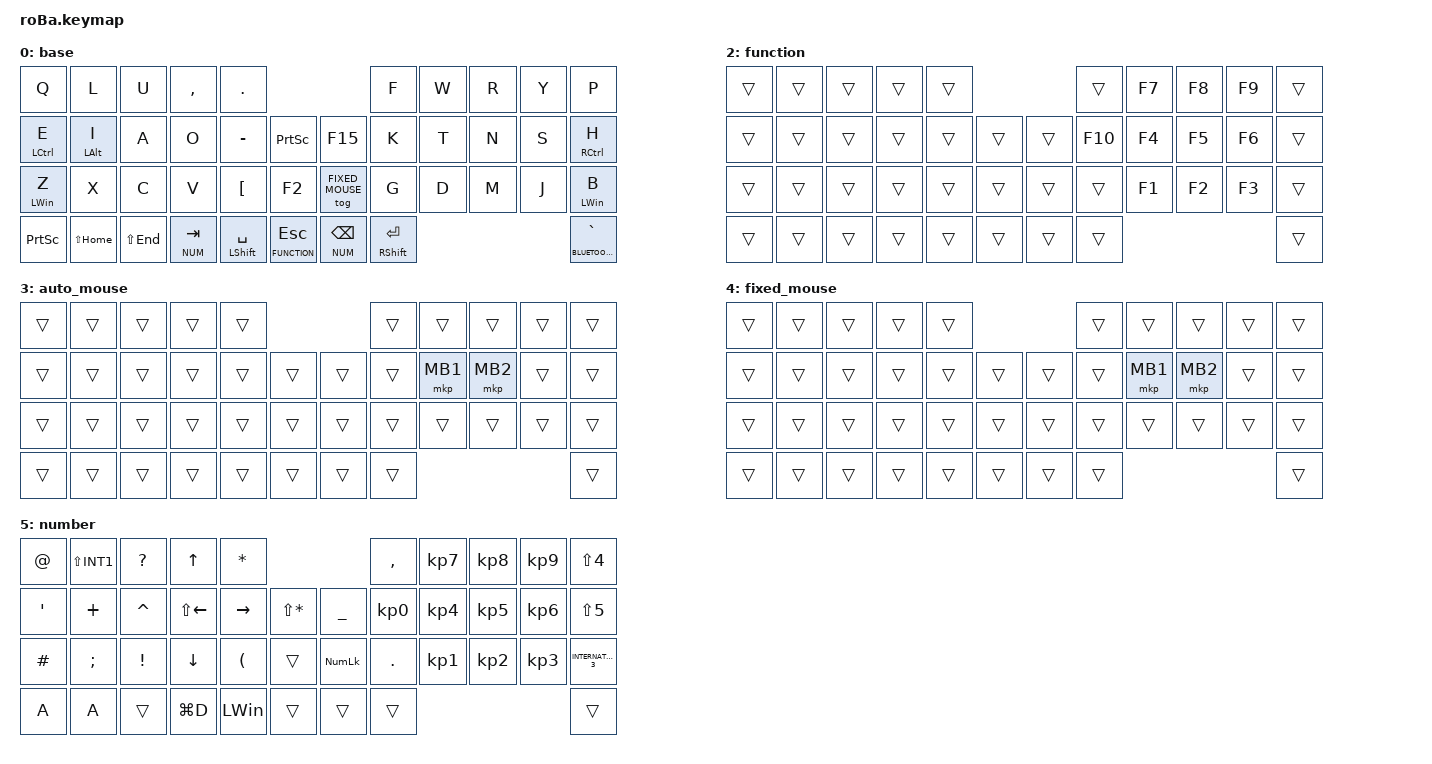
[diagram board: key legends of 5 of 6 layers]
#include <behaviors.dtsi>
#include <dt-bindings/zmk/bt.h>
#include <dt-bindings/zmk/keys.h>
#include <dt-bindings/zmk/pointing.h>
#include <dt-bindings/zmk/modifiers.h>

/* Encoder wheel: ensure a 20ms rotary pulse produces usable scroll. */
#define ZMK_POINTING_DEFAULT_SCRL_VAL 80

/*
 * レイヤー番号（数字レイヤーを1枚に統合）
 *
 * 0 = base          通常
 * 1 = bluetooth     Bluetooth接続先
 * 2 = function      F1～F10
 * 3 = auto_mouse    オートマウス
 * 4 = fixed_mouse   手動固定マウス
 * 5 = number        数字・記号
 *
 * NUMBERをFIXED_MOUSEより上に置くことで、
 * fixed_mouse中でも同じNUMBERレイヤーをそのまま使用できる。
 * 旧fixed_number条件レイヤーは不要。
 */

#define BASE 0
#define BLUETOOTH 1
#define FUNCTION 2
#define AUTO_MOUSE 3
#define FIXED_MOUSE 4
#define NUM 5

&mt {
    flavor = "balanced";
    quick-tap-ms = <0>;
};

/ {
    combos {
        compatible = "zmk,combos";

        mb3 {
            bindings = <&mkp MB3>;
            key-positions = <18 19>;
            timeout-ms = <40>;
            layers = <AUTO_MOUSE FIXED_MOUSE>;
        };

        /*
         * BASEでは W+R / R+Y を * / に使用するため、
         * MB4 / MB5 はBASEから除外する。
         * AUTO_MOUSE / FIXED_MOUSEでは従来どおりMB4 / MB5。
         */

        mb4 {
            bindings = <&mkp MB4>;
            key-positions = <6 7>;
            timeout-ms = <80>;
            layers = <BLUETOOTH FUNCTION AUTO_MOUSE FIXED_MOUSE>;
        };

        mb5 {
            bindings = <&mkp MB5>;
            key-positions = <7 8>;
            timeout-ms = <80>;
            layers = <BLUETOOTH FUNCTION AUTO_MOUSE FIXED_MOUSE>;
        };

        left {
            bindings = <&kp LEFT_ARROW>;
            key-positions = <11 12>;
            timeout-ms = <80>;
        };

        right {
            bindings = <&kp RIGHT_ARROW>;
            key-positions = <12 13>;
            timeout-ms = <80>;
        };

        up {
            bindings = <&kp UP_ARROW>;
            key-positions = <1 2>;
            timeout-ms = <80>;
        };

        down {
            bindings = <&kp DOWN_ARROW>;
            key-positions = <23 24>;
            timeout-ms = <80>;
        };

        esc {
            bindings = <&kp ESC>;
            key-positions = <1 0>;
            timeout-ms = <80>;
        };

        del2 {
            bindings = <&kp ESCAPE>;
            key-positions = <8 9>;
            timeout-ms = <80>;
        };

        cv_ctrl_backspace {
            bindings = <&kp LC(BACKSPACE)>;
            key-positions = <24 25>;
            timeout-ms = <80>;
        };

        dm_ctrl_delete {
            bindings = <&kp LC(DELETE)>;
            key-positions = <30 31>;
            timeout-ms = <80>;
        };

        hankaku {
            bindings = <&kp GRAVE>;
            key-positions = <20 21>;
            timeout-ms = <80>;
        };

        ei_f10 {
            bindings = <&kp F10>;
            key-positions = <10 11>;
            timeout-ms = <80>;
        };

        zx_f7 {
            bindings = <&kp F7>;
            key-positions = <22 23>;
            timeout-ms = <80>;
        };

        xv_home {
            bindings = <&kp HOME>;
            key-positions = <23 25>;
            timeout-ms = <80>;
        };

        io_win_h {
            bindings = <&kp LG(H)>;
            key-positions = <11 13>;
            timeout-ms = <80>;
        };

        mj_delete {
            bindings = <&kp DELETE>;
            key-positions = <31 32>;
            timeout-ms = <80>;
        };

        dj_end {
            bindings = <&kp END>;
            key-positions = <30 32>;
            timeout-ms = <80>;
        };

        /*
         * 演算子コンボはBASEとNUMBERの両方で有効。
         *
         * BASE:
         * T+S = =
         * W+R = *
         * R+Y = /
         * T+N = +
         * N+S = -
         *
         * AUTO_MOUSE / FIXED_MOUSEでは W+R / R+Y はMB4 / MB5を優先。
         *
         * Windows日本語配列:
         * - "=" はKP_EQUALがWindows非対応なので、従来どおり
         *   Shift+Minus相当のUNDERを使用する。
         * - * + - / はWindows対応のテンキー演算子を使う。
         */

        num_46_equal {
            bindings = <&kp UNDER>;
            key-positions = <18 20>;
            timeout-ms = <80>;
            layers = <BASE NUM>;
        };

        num_78_multiply {
            bindings = <&kp KP_MULTIPLY>;
            key-positions = <6 7>;
            timeout-ms = <80>;
            layers = <BASE NUM>;
        };

        num_89_divide {
            bindings = <&kp KP_DIVIDE>;
            key-positions = <7 8>;
            timeout-ms = <80>;
            layers = <BASE NUM>;
        };

        num_45_plus {
            bindings = <&kp KP_PLUS>;
            key-positions = <18 19>;
            timeout-ms = <80>;
            layers = <BASE NUM>;
        };

        num_56_minus {
            bindings = <&kp KP_MINUS>;
            key-positions = <19 20>;
            timeout-ms = <80>;
            layers = <BASE NUM>;
        };

        f4 {
            bindings = <&kp F4>;
            key-positions = <32 33>;
            timeout-ms = <80>;
        };
    };

    behaviors {
        ctrl_mt: ctrl_mt {
            compatible = "zmk,behavior-hold-tap";
            label = "CTRL_MT";
            #binding-cells = <2>;
            flavor = "balanced";
            tapping-term-ms = <200>;
            quick-tap-ms = <0>;
            hold-while-undecided;
            bindings = <&kp>, <&kp>;
        };

        shift_mt: shift_mt {
            compatible = "zmk,behavior-hold-tap";
            label = "SHIFT_MT";
            #binding-cells = <2>;
            flavor = "balanced";
            tapping-term-ms = <200>;
            quick-tap-ms = <0>;
            hold-while-undecided;
            bindings = <&kp>, <&kp>;
        };

        /* Reverse normal wheel, but retain the original Ctrl+wheel zoom direction. */
        encoder_cw: encoder_cw {
            compatible = "zmk,behavior-mod-morph";
            #binding-cells = <0>;
            bindings = <&msc SCRL_DOWN>, <&msc SCRL_UP>;
            mods = <(MOD_LCTL|MOD_RCTL)>;
            keep-mods = <(MOD_LCTL|MOD_RCTL)>;
        };

        encoder_ccw: encoder_ccw {
            compatible = "zmk,behavior-mod-morph";
            #binding-cells = <0>;
            bindings = <&msc SCRL_UP>, <&msc SCRL_DOWN>;
            mods = <(MOD_LCTL|MOD_RCTL)>;
            keep-mods = <(MOD_LCTL|MOD_RCTL)>;
        };

        encoder_wheel: encoder_wheel {
            compatible = "zmk,behavior-sensor-rotate";
            #sensor-binding-cells = <0>;
            bindings = <&encoder_cw>, <&encoder_ccw>;
            tap-ms = <20>;
        };

        pgdn_pgup: pgdn_pgup {
            compatible = "zmk,behavior-mod-morph";
            label = "PGDN_PGUP";
            bindings = <&kp PAGE_DOWN>, <&kp PAGE_UP>;

            #binding-cells = <0>;
            mods = <(MOD_LSFT|MOD_RSFT)>;
        };
    };

    keymap {
        compatible = "zmk,keymap";

        /* Layer 0 */

        base {
            bindings = <
&kp Q             &kp L           &kp U        &kp COMMA    &kp DOT                                                             &kp F                        &kp W  &kp R  &kp Y  &kp P
&ctrl_mt LCTRL E  &mt LEFT_ALT I  &kp A        &kp O        &kp MINUS               &kp PRINTSCREEN          &kp F15            &kp K                        &kp T  &kp N  &kp S  &ctrl_mt RCTRL H
&mt LEFT_WIN Z    &kp X           &kp C        &kp V        &kp LEFT_BRACKET        &kp F2                   &tog FIXED_MOUSE   &kp G                        &kp D  &kp M  &kp J  &mt LEFT_WIN B
&kp PRINTSCREEN   &kp LS(HOME)    &kp LS(END)  &lt NUM TAB  &shift_mt LSHIFT SPACE  &lt FUNCTION ESCAPE      &lt NUM BACKSPACE  &shift_mt RIGHT_SHIFT ENTER                       &lt BLUETOOTH GRAVE
            >;

            sensor-bindings = <&encoder_wheel>;
        };

        /* Layer 1 */

        bluetooth {
            bindings = <
&trans  &trans  &trans  &trans  &trans                              &bt BT_SEL 0  &bt BT_SEL 1  &bt BT_SEL 2  &bt BT_SEL 3  &bt BT_SEL 4
&trans  &trans  &trans  &trans  &trans  &trans      &trans          &trans        &trans        &trans        &trans        &trans
&trans  &trans  &trans  &trans  &trans  &trans      &trans          &trans        &trans        &trans        &trans        &trans
&trans  &trans  &trans  &trans  &trans  &trans      &bt BT_CLR_ALL  &trans
            >;

            sensor-bindings = <&encoder_wheel>;
        };

        /* Layer 2 */

        function {
            bindings = <
&trans  &trans  &trans  &trans  &trans                      &trans   &kp F7  &kp F8  &kp F9  &trans
&trans  &trans  &trans  &trans  &trans  &trans      &trans  &kp F10  &kp F4  &kp F5  &kp F6  &trans
&trans  &trans  &trans  &trans  &trans  &trans      &trans  &trans   &kp F1  &kp F2  &kp F3  &trans
&trans  &trans  &trans  &trans  &trans  &trans      &trans  &trans                           &trans
            >;

            sensor-bindings = <&encoder_wheel>;
        };

        /* Layer 3 */

        auto_mouse {
            bindings = <
&trans  &trans  &trans  &trans  &trans                      &trans  &trans    &trans    &trans  &trans
&trans  &trans  &trans  &trans  &trans  &trans      &trans  &trans  &mkp MB1  &mkp MB2  &trans  &trans
&trans  &trans  &trans  &trans  &trans  &trans      &trans  &trans  &trans    &trans    &trans  &trans
&trans  &trans  &trans  &trans  &trans  &trans      &trans  &trans                              &trans
            >;

            sensor-bindings = <&encoder_wheel>;
        };

        /* Layer 4 */

        fixed_mouse {
            bindings = <
&trans  &trans  &trans  &trans  &trans                      &trans  &trans    &trans    &trans  &trans
&trans  &trans  &trans  &trans  &trans  &trans      &trans  &trans  &mkp MB1  &mkp MB2  &trans  &trans
&trans  &trans  &trans  &trans  &trans  &trans      &trans  &trans  &trans    &trans    &trans  &trans
&trans  &trans  &trans  &trans  &trans  &trans      &trans  &trans                              &trans
            >;

            sensor-bindings = <&encoder_wheel>;
        };

        /*
         * Layer 5: 数字・記号
         *
         * 0～9はテンキーHIDを使用して、Windows日本語IME環境で
         * 半角数字として扱われやすくする。
         * * + - はテンキー演算子。
         * "=" はWindowsがKP_EQUAL非対応のためUNDERを使用。
         *
         * NumLockがOFFの場合、KP_N0～KP_N9はナビゲーションキーとして
         * 動くため、Windows側のNumLockはONで使用する。
         */

        number {
            bindings = <
&kp AT_SIGN  &kp LS(INT1)  &kp QUESTION     &kp UP_ARROW        &kp ASTERISK                                             &kp COMMA   &kp KP_N7  &kp KP_N8  &kp KP_N9  &kp LS(NUMBER_4)
&kp SQT      &kp PLUS      &kp CARET        &kp LS(LEFT_ARROW)  &kp RIGHT_ARROW       &kp LS(ASTRK)      &kp UNDERSCORE  &kp KP_N0   &kp KP_N4  &kp KP_N5  &kp KP_N6  &kp LS(N5)
&kp HASH     &kp SEMI      &kp EXCLAMATION  &kp DOWN_ARROW      &kp LEFT_PARENTHESIS  &trans             &kp KP_NUMLOCK  &kp PERIOD  &kp KP_N1  &kp KP_N2  &kp KP_N3  &kp INTERNATIONAL_3
&kp A        &kp A         &trans           &kp LG(D)           &kp LEFT_WIN          &trans             &trans          &trans                                       &trans
            >;

            sensor-bindings = <&encoder_wheel>;
        };
    };
};
